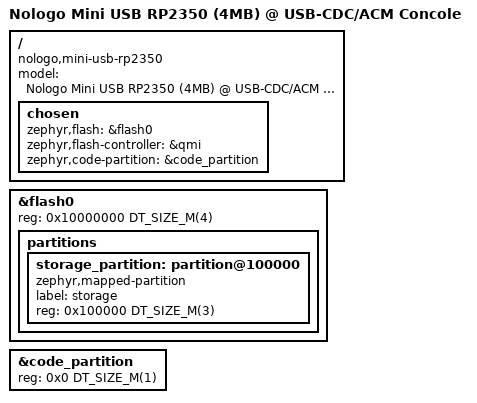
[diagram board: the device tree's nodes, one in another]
/*
 * SPDX-FileCopyrightText: Copyright (c) 2025-2026 TiaC Systems
 * SPDX-License-Identifier: Apache-2.0
 */

#include <mem.h>

#include <raspberrypi/partitions_0x0_default_4M.dtsi>

/ {
	model = "Nologo Mini USB RP2350 (4MB) @ USB-CDC/ACM Concole";
	compatible = "nologo,mini-usb-rp2350",
		     "nologo,mini-usb-rp2350-usbcons",
		     "nologo,mini-usb-rp2350-4mb",
		     "nologo,mini-usb-rp2350-4mb-usbcons";

	chosen {
		zephyr,flash = &flash0;
		zephyr,flash-controller = &qmi;
		zephyr,code-partition = &code_partition;
	};
};

&flash0 {
	status = "okay";
	reg = <0x10000000 DT_SIZE_M(4)>;
	ranges = <0x0 0x10000000 DT_SIZE_M(4)>;

	partitions {
		storage_partition: partition@100000 {
			compatible = "zephyr,mapped-partition";
			label = "storage";
			reg = <0x100000 DT_SIZE_M(3)>;
		};
	};
};

&code_partition {
	reg = <0x0 DT_SIZE_M(1)>;
};
